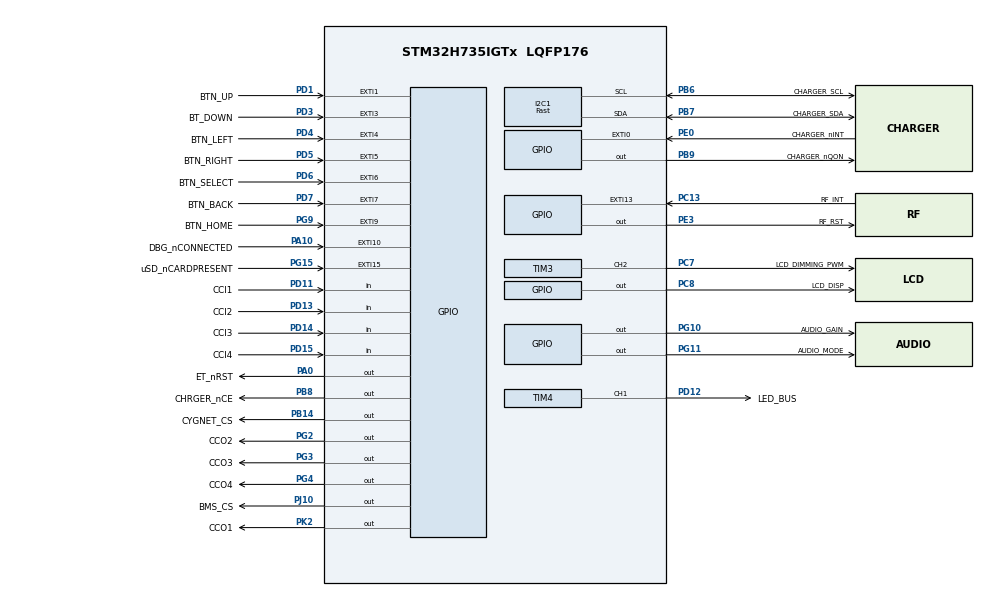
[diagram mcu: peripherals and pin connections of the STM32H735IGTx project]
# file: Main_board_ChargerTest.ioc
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CORTEX_M7.AccessPermission-Cortex_Memory_Protection_Unit_Region1_Settings=MPU_REGION_FULL_ACCESS
CORTEX_M7.BaseAddress-Cortex_Memory_Protection_Unit_Region1_Settings=0x30000000
CORTEX_M7.BaseAddress-Cortex_Memory_Protection_Unit_Region2_Settings=0x30000000
CORTEX_M7.CPU_DCache=Enabled
CORTEX_M7.CPU_ICache=Enabled
CORTEX_M7.DisableExec-Cortex_Memory_Protection_Unit_Region0_Settings=MPU_INSTRUCTION_ACCESS_DISABLE
CORTEX_M7.DisableExec-Cortex_Memory_Protection_Unit_Region1_Settings=MPU_INSTRUCTION_ACCESS_DISABLE
CORTEX_M7.DisableExec-Cortex_Memory_Protection_Unit_Region2_Settings=MPU_INSTRUCTION_ACCESS_DISABLE
CORTEX_M7.Enable-Cortex_Memory_Protection_Unit_Region0_Settings=MPU_REGION_ENABLE
CORTEX_M7.Enable-Cortex_Memory_Protection_Unit_Region1_Settings=MPU_REGION_ENABLE
CORTEX_M7.Enable-Cortex_Memory_Protection_Unit_Region2_Settings=MPU_REGION_ENABLE
CORTEX_M7.IsCacheable-Cortex_Memory_Protection_Unit_Region2_Settings=MPU_ACCESS_CACHEABLE
CORTEX_M7.IsShareable-Cortex_Memory_Protection_Unit_Region0_Settings=MPU_ACCESS_SHAREABLE
CORTEX_M7.MPU_Control=MPU_HFNMI_PRIVDEF
CORTEX_M7.Size-Cortex_Memory_Protection_Unit_Region0_Settings=MPU_REGION_SIZE_4GB
CORTEX_M7.Size-Cortex_Memory_Protection_Unit_Region1_Settings=MPU_REGION_SIZE_32KB
CORTEX_M7.Size-Cortex_Memory_Protection_Unit_Region2_Settings=MPU_REGION_SIZE_512B
CORTEX_M7.SubRegionDisable-Cortex_Memory_Protection_Unit_Region0_Settings=0x87
I2C1.I2C_Speed_Mode=I2C_Fast
I2C1.Speed=50
I2C1.Timing=0xC0102FA1
Mcu.Family=STM32H7
Mcu.Name=STM32H735IGTx
Mcu.Package=LQFP176
NVIC.PriorityGroup=NVIC_PRIORITYGROUP_4
PA0.GPIO_Label=ET_nRST
PA0.Signal=GPIO_Output
PA10.GPIO_Label=DBG_nCONNECTED
PA10.GPIO_ModeDefaultEXTI=GPIO_MODE_IT_FALLING
PA10.Signal=GPXTI10
PA13(JTMS/SWDIO).Mode=Trace_Asynchronous_SW
PA13(JTMS/SWDIO).Signal=DEBUG_JTMS-SWDIO
PA14(JTCK/SWCLK).Mode=Trace_Asynchronous_SW
PA14(JTCK/SWCLK).Signal=DEBUG_JTCK-SWCLK
PB14.GPIO_Label=CYGNET_CS
PB14.Signal=GPIO_Output
PB3(JTDO/TRACESWO).Mode=Trace_Asynchronous_SW
PB3(JTDO/TRACESWO).Signal=DEBUG_JTDO-SWO
PB6.GPIO_Label=CHARGER_SCL
PB6.GPIO_Speed=GPIO_SPEED_FREQ_HIGH
PB6.Mode=I2C
PB6.Signal=I2C1_SCL
PB7.GPIO_Label=CHARGER_SDA
PB7.GPIO_Speed=GPIO_SPEED_FREQ_HIGH
PB7.Mode=I2C
PB7.Signal=I2C1_SDA
PB8.GPIO_Label=CHRGER_nCE
PB8.PinState=GPIO_PIN_SET
PB8.Signal=GPIO_Output
PB9.GPIO_Label=CHARGER_nQON
PB9.PinState=GPIO_PIN_SET
PB9.Signal=GPIO_Output
PC10.GPIO_Label=LCD_R2
PC10.GPIO_Speed=GPIO_SPEED_FREQ_VERY_HIGH
PC10.Signal=LTDC_R2
PC11.GPIO_Label=FLASH_nCS
PC11.Signal=OCTOSPIM_P1_NCS
PC13.GPIO_Label=RF_INT
PC13.Signal=GPXTI13
PC14-OSC32_IN.Mode=LSE-External-Oscillator
PC14-OSC32_IN.Signal=RCC_OSC32_IN
PC15-OSC32_OUT.Mode=LSE-External-Oscillator
PC15-OSC32_OUT.Signal=RCC_OSC32_OUT
PC7.GPIO_Label=LCD_DIMMING_PWM
PC7.Signal=S_TIM3_CH2
PC8.GPIO_Label=LCD_DISP
PC8.Signal=GPIO_Output
PD1.GPIO_Label=BTN_UP
PD1.Signal=GPXTI1
PD11.GPIO_Label=CCI1
PD11.Signal=GPIO_Input
PD12.GPIO_Label=LED_BUS
PD12.GPIO_Speed=GPIO_SPEED_FREQ_MEDIUM
PD12.Signal=S_TIM4_CH1
PD13.GPIO_Label=CCI2
PD13.Signal=GPIO_Input
PD14.GPIO_Label=CCI3
PD14.Signal=GPIO_Input
PD15.GPIO_Label=CCI4
PD15.Signal=GPIO_Input
PD3.GPIO_Label=BT_DOWN
PD3.Signal=GPXTI3
PD4.GPIO_Label=BTN_LEFT
PD4.Signal=GPXTI4
PD5.GPIO_Label=BTN_RIGHT
PD5.Signal=GPXTI5
PD6.GPIO_Label=BTN_SELECT
PD6.Signal=GPXTI6
PD7.GPIO_Label=BTN_BACK
PD7.Signal=GPXTI7
PE0.GPIO_Label=CHARGER_nINT
PE0.GPIO_ModeDefaultEXTI=GPIO_MODE_IT_FALLING
PE0.Signal=GPXTI0
PE3.GPIO_Label=RF_RST
PE3.Signal=GPIO_Output
PF7.GPIO_Label=FLASH_D2
PF7.Signal=OCTOSPIM_P1_IO2
PG10.GPIO_Label=AUDIO_GAIN
PG10.Signal=GPIO_Output
PG11.GPIO_Label=AUDIO_MODE
PG11.Signal=GPIO_Output
PG13.GPIO_Label=BCLK
PG13.Signal=I2S6_CK
PG15.GPIO_Label=uSD_nCARDPRESENT
PG15.GPIO_ModeDefaultEXTI=GPIO_MODE_IT_FALLING
PG15.Signal=GPXTI15
PG2.GPIO_Label=CCO2
PG2.Signal=GPIO_Output
PG3.GPIO_Label=CCO3
PG3.GPIO_Speed=GPIO_SPEED_FREQ_LOW
PG3.Signal=GPIO_Output
PG4.GPIO_Label=CCO4
PG4.Signal=GPIO_Output
PG8.GPIO_Label=LRCK
PG8.Signal=I2S6_WS
PG9.GPIO_Label=BTN_HOME
PG9.Signal=GPXTI9
PH0-OSC_IN.Mode=HSE-External-Oscillator
PH0-OSC_IN.Signal=RCC_OSC_IN
PH1-OSC_OUT.Mode=HSE-External-Oscillator
PH1-OSC_OUT.Signal=RCC_OSC_OUT
PJ10.GPIO_Label=BMS_CS
PJ10.Signal=GPIO_Output
PK2.GPIO_Label=CCO1
PK2.Signal=GPIO_Output
ProjectManager.HeapSize=0x200
ProjectManager.StackSize=0x400
ProjectManager.TargetToolchain=MDK-ARM V5
RCC.ADCFreq_Value=96000671.38671875
RCC.APB1Freq_Value=137500000
RCC.APB2Freq_Value=137500000
RCC.APB3Freq_Value=137500000
RCC.APB4Freq_Value=137500000
RCC.CortexFreq_Value=550000000
RCC.D1PPRE=RCC_APB3_DIV2
RCC.D2PPRE1=RCC_APB1_DIV2
RCC.D2PPRE2=RCC_APB2_DIV2
RCC.D3PPRE=RCC_APB4_DIV2
RCC.DIVM1=2
RCC.DIVM2=2
RCC.DIVN1=44
RCC.DIVN2=15
RCC.DIVP1=1
RCC.DIVQ1=5
RCC.HCLKFreq_Value=275000000
RCC.HPRE=RCC_HCLK_DIV2
RCC.PLL1_VCO_SEL-AdvancedSettings=RCC_PLL1VCOWIDE
RCC.PLL2FRACN=2950
RCC.PLL2_VCI_Range-AdvancedSettings=RCC_PLL2VCIRANGE_3
RCC.PLL3FRACN=0
RCC.PLLFRACN=0
RCC.PLLSourceVirtual=RCC_PLLSOURCE_HSE
RCC.SPI123CLockSelection=RCC_SPI123CLKSOURCE_CLKP
RCC.SYSCLKFreq_VALUE=550000000
RCC.SYSCLKSource=RCC_SYSCLKSOURCE_PLLCLK
RCC.USBCLockSelection=RCC_USBCLKSOURCE_HSI48
RCC.USBFreq_Value=48000000
SH.S_TIM3_CH2.0=TIM3_CH2,Output Compare2 CH2
SH.S_TIM4_CH1.0=TIM4_CH1,PWM Generation1 CH1
TIM3.Channel-Output\ Compare2\ CH2=TIM_CHANNEL_2
TIM4.Channel-PWM\ Generation1\ CH1=TIM_CHANNEL_1
VP_TIM3_VS_ClockSourceINT.Mode=Internal
VP_TIM4_VS_ClockSourceINT.Mode=Internal
board=custom

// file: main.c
/* USER CODE BEGIN Header */
/**
  ******************************************************************************
  * @file           : main.c
  * @brief          : Main program body
  ******************************************************************************
  * @attention
  *
  * Copyright (c) 2024 STMicroelectronics.
  * All rights reserved.
  *
  * This software is licensed under terms that can be found in the LICENSE file
  * in the root directory of this software component.
  * If no LICENSE file comes with this software, it is provided AS-IS.
  *
  ******************************************************************************
  */
/* USER CODE END Header */
#include "main.h"

/* USER CODE BEGIN Includes */

#include "I2C_charger.h"
/* USER CODE END Includes */

I2C_HandleTypeDef hi2c1;

TIM_HandleTypeDef htim3;
TIM_HandleTypeDef htim4;

void SystemClock_Config(void);
static void MPU_Config(void);
static void MX_GPIO_Init(void);
static void MX_I2C1_Init(void);
static void MX_TIM3_Init(void);
static void MX_TIM4_Init(void);

int main(void)
{

  /* MPU Configuration--------------------------------------------------------*/
  MPU_Config();
/* Enable the CPU Cache */

  /* Enable I-Cache---------------------------------------------------------*/
  SCB_EnableICache();

  /* Enable D-Cache---------------------------------------------------------*/
  SCB_EnableDCache();

  /* MCU Configuration--------------------------------------------------------*/

  /* Reset of all peripherals, Initializes the Flash interface and the Systick. */
  HAL_Init();

  /* Configure the system clock */
  SystemClock_Config();

  /* Initialize all configured peripherals */
  MX_GPIO_Init();
  MX_I2C1_Init();
  MX_TIM3_Init();
  MX_TIM4_Init();

  /* Infinite loop */
  /* USER CODE BEGIN WHILE */

	HAL_Delay(500);

  while (1)
  {
    /* USER CODE END WHILE */

    /* USER CODE BEGIN 3 */

	Power_Supply_Thread();

  }
  /* USER CODE END 3 */
}

void SystemClock_Config(void)
{
  RCC_OscInitTypeDef RCC_OscInitStruct = {0};
  RCC_ClkInitTypeDef RCC_ClkInitStruct = {0};

  /** Supply configuration update enable
  */
  HAL_PWREx_ConfigSupply(PWR_DIRECT_SMPS_SUPPLY);

  /** Configure the main internal regulator output voltage
  */
  __HAL_PWR_VOLTAGESCALING_CONFIG(PWR_REGULATOR_VOLTAGE_SCALE0);

  while(!__HAL_PWR_GET_FLAG(PWR_FLAG_VOSRDY)) {}

  /** Initializes the RCC Oscillators according to the specified parameters
  * in the RCC_OscInitTypeDef structure.
  */
  RCC_OscInitStruct.OscillatorType = RCC_OSCILLATORTYPE_HSE;
  RCC_OscInitStruct.HSEState = RCC_HSE_ON;
  RCC_OscInitStruct.PLL.PLLState = RCC_PLL_ON;
  RCC_OscInitStruct.PLL.PLLSource = RCC_PLLSOURCE_HSE;
  RCC_OscInitStruct.PLL.PLLM = 2;
  RCC_OscInitStruct.PLL.PLLN = 44;
  RCC_OscInitStruct.PLL.PLLP = 1;
  RCC_OscInitStruct.PLL.PLLQ = 5;
  RCC_OscInitStruct.PLL.PLLR = 2;
  RCC_OscInitStruct.PLL.PLLRGE = RCC_PLL1VCIRANGE_3;
  RCC_OscInitStruct.PLL.PLLVCOSEL = RCC_PLL1VCOWIDE;
  RCC_OscInitStruct.PLL.PLLFRACN = 0;
  if (HAL_RCC_OscConfig(&RCC_OscInitStruct) != HAL_OK)
  {
    Error_Handler();
  }

  /** Initializes the CPU, AHB and APB buses clocks
  */
  RCC_ClkInitStruct.ClockType = RCC_CLOCKTYPE_HCLK|RCC_CLOCKTYPE_SYSCLK
                              |RCC_CLOCKTYPE_PCLK1|RCC_CLOCKTYPE_PCLK2
                              |RCC_CLOCKTYPE_D3PCLK1|RCC_CLOCKTYPE_D1PCLK1;
  RCC_ClkInitStruct.SYSCLKSource = RCC_SYSCLKSOURCE_PLLCLK;
  RCC_ClkInitStruct.SYSCLKDivider = RCC_SYSCLK_DIV1;
  RCC_ClkInitStruct.AHBCLKDivider = RCC_HCLK_DIV2;
  RCC_ClkInitStruct.APB3CLKDivider = RCC_APB3_DIV2;
  RCC_ClkInitStruct.APB1CLKDivider = RCC_APB1_DIV2;
  RCC_ClkInitStruct.APB2CLKDivider = RCC_APB2_DIV2;
  RCC_ClkInitStruct.APB4CLKDivider = RCC_APB4_DIV2;

  if (HAL_RCC_ClockConfig(&RCC_ClkInitStruct, FLASH_LATENCY_3) != HAL_OK)
  {
    Error_Handler();
  }
}

static void MX_I2C1_Init(void)
{

  hi2c1.Instance = I2C1;
  hi2c1.Init.Timing = 0xC0102FA1;
  hi2c1.Init.OwnAddress1 = 0;
  hi2c1.Init.AddressingMode = I2C_ADDRESSINGMODE_7BIT;
  hi2c1.Init.DualAddressMode = I2C_DUALADDRESS_DISABLE;
  hi2c1.Init.OwnAddress2 = 0;
  hi2c1.Init.OwnAddress2Masks = I2C_OA2_NOMASK;
  hi2c1.Init.GeneralCallMode = I2C_GENERALCALL_DISABLE;
  hi2c1.Init.NoStretchMode = I2C_NOSTRETCH_DISABLE;
  if (HAL_I2C_Init(&hi2c1) != HAL_OK)
  {
    Error_Handler();
  }

  /** Configure Analogue filter
  */
  if (HAL_I2CEx_ConfigAnalogFilter(&hi2c1, I2C_ANALOGFILTER_ENABLE) != HAL_OK)
  {
    Error_Handler();
  }

  /** Configure Digital filter
  */
  if (HAL_I2CEx_ConfigDigitalFilter(&hi2c1, 0) != HAL_OK)
  {
    Error_Handler();
  }

}

static void MX_TIM3_Init(void)
{

  TIM_ClockConfigTypeDef sClockSourceConfig = {0};
  TIM_MasterConfigTypeDef sMasterConfig = {0};
  TIM_OC_InitTypeDef sConfigOC = {0};

  htim3.Instance = TIM3;
  htim3.Init.Prescaler = 0;
  htim3.Init.CounterMode = TIM_COUNTERMODE_UP;
  htim3.Init.Period = 65535;
  htim3.Init.ClockDivision = TIM_CLOCKDIVISION_DIV1;
  htim3.Init.AutoReloadPreload = TIM_AUTORELOAD_PRELOAD_DISABLE;
  if (HAL_TIM_Base_Init(&htim3) != HAL_OK)
  {
    Error_Handler();
  }
  sClockSourceConfig.ClockSource = TIM_CLOCKSOURCE_INTERNAL;
  if (HAL_TIM_ConfigClockSource(&htim3, &sClockSourceConfig) != HAL_OK)
  {
    Error_Handler();
  }
  if (HAL_TIM_OC_Init(&htim3) != HAL_OK)
  {
    Error_Handler();
  }
  sMasterConfig.MasterOutputTrigger = TIM_TRGO_RESET;
  sMasterConfig.MasterSlaveMode = TIM_MASTERSLAVEMODE_DISABLE;
  if (HAL_TIMEx_MasterConfigSynchronization(&htim3, &sMasterConfig) != HAL_OK)
  {
    Error_Handler();
  }
  sConfigOC.OCMode = TIM_OCMODE_TIMING;
  sConfigOC.Pulse = 0;
  sConfigOC.OCPolarity = TIM_OCPOLARITY_HIGH;
  sConfigOC.OCFastMode = TIM_OCFAST_DISABLE;
  if (HAL_TIM_OC_ConfigChannel(&htim3, &sConfigOC, TIM_CHANNEL_2) != HAL_OK)
  {
    Error_Handler();
  }
  HAL_TIM_MspPostInit(&htim3);

}

static void MX_TIM4_Init(void)
{

  TIM_ClockConfigTypeDef sClockSourceConfig = {0};
  TIM_MasterConfigTypeDef sMasterConfig = {0};
  TIM_OC_InitTypeDef sConfigOC = {0};

  htim4.Instance = TIM4;
  htim4.Init.Prescaler = 0;
  htim4.Init.CounterMode = TIM_COUNTERMODE_UP;
  htim4.Init.Period = 65535;
  htim4.Init.ClockDivision = TIM_CLOCKDIVISION_DIV1;
  htim4.Init.AutoReloadPreload = TIM_AUTORELOAD_PRELOAD_DISABLE;
  if (HAL_TIM_Base_Init(&htim4) != HAL_OK)
  {
    Error_Handler();
  }
  sClockSourceConfig.ClockSource = TIM_CLOCKSOURCE_INTERNAL;
  if (HAL_TIM_ConfigClockSource(&htim4, &sClockSourceConfig) != HAL_OK)
  {
    Error_Handler();
  }
  if (HAL_TIM_PWM_Init(&htim4) != HAL_OK)
  {
    Error_Handler();
  }
  sMasterConfig.MasterOutputTrigger = TIM_TRGO_RESET;
  sMasterConfig.MasterSlaveMode = TIM_MASTERSLAVEMODE_DISABLE;
  if (HAL_TIMEx_MasterConfigSynchronization(&htim4, &sMasterConfig) != HAL_OK)
  {
    Error_Handler();
  }
  sConfigOC.OCMode = TIM_OCMODE_PWM1;
  sConfigOC.Pulse = 0;
  sConfigOC.OCPolarity = TIM_OCPOLARITY_HIGH;
  sConfigOC.OCFastMode = TIM_OCFAST_DISABLE;
  if (HAL_TIM_PWM_ConfigChannel(&htim4, &sConfigOC, TIM_CHANNEL_1) != HAL_OK)
  {
    Error_Handler();
  }
  HAL_TIM_MspPostInit(&htim4);

}

static void MX_GPIO_Init(void)
{
  GPIO_InitTypeDef GPIO_InitStruct = {0};

  /* GPIO Ports Clock Enable */
  __HAL_RCC_GPIOE_CLK_ENABLE();
  __HAL_RCC_GPIOC_CLK_ENABLE();
  __HAL_RCC_GPIOF_CLK_ENABLE();
  __HAL_RCC_GPIOH_CLK_ENABLE();
  __HAL_RCC_GPIOA_CLK_ENABLE();
  __HAL_RCC_GPIOB_CLK_ENABLE();
  __HAL_RCC_GPIOD_CLK_ENABLE();
  __HAL_RCC_GPIOJ_CLK_ENABLE();
  __HAL_RCC_GPIOK_CLK_ENABLE();
  __HAL_RCC_GPIOG_CLK_ENABLE();

  /*Configure GPIO pin Output Level */
  HAL_GPIO_WritePin(RF_RST_GPIO_Port, RF_RST_Pin, GPIO_PIN_RESET);

  /*Configure GPIO pin Output Level */
  HAL_GPIO_WritePin(ET_nRST_GPIO_Port, ET_nRST_Pin, GPIO_PIN_RESET);

  /*Configure GPIO pin Output Level */
  HAL_GPIO_WritePin(CYGNET_CS_GPIO_Port, CYGNET_CS_Pin, GPIO_PIN_RESET);

  /*Configure GPIO pin Output Level */
  HAL_GPIO_WritePin(BMS_CS_GPIO_Port, BMS_CS_Pin, GPIO_PIN_RESET);

  /*Configure GPIO pin Output Level */
  HAL_GPIO_WritePin(CCO1_GPIO_Port, CCO1_Pin, GPIO_PIN_RESET);

  /*Configure GPIO pin Output Level */
  HAL_GPIO_WritePin(GPIOG, CCO2_Pin|CCO3_Pin|CCO4_Pin|AUDIO_GAIN_Pin
                          |AUDIO_MODE_Pin, GPIO_PIN_RESET);

  /*Configure GPIO pin Output Level */
  HAL_GPIO_WritePin(LCD_DISP_GPIO_Port, LCD_DISP_Pin, GPIO_PIN_RESET);

  /*Configure GPIO pin Output Level */
  HAL_GPIO_WritePin(GPIOB, CHRGER_nCE_Pin|CHARGER_nQON_Pin, GPIO_PIN_SET);

  /*Configure GPIO pin : RF_RST_Pin */
  GPIO_InitStruct.Pin = RF_RST_Pin;
  GPIO_InitStruct.Mode = GPIO_MODE_OUTPUT_PP;
  GPIO_InitStruct.Pull = GPIO_NOPULL;
  GPIO_InitStruct.Speed = GPIO_SPEED_FREQ_LOW;
  HAL_GPIO_Init(RF_RST_GPIO_Port, &GPIO_InitStruct);

  /*Configure GPIO pin : RF_INT_Pin */
  GPIO_InitStruct.Pin = RF_INT_Pin;
  GPIO_InitStruct.Mode = GPIO_MODE_IT_RISING;
  GPIO_InitStruct.Pull = GPIO_NOPULL;
  HAL_GPIO_Init(RF_INT_GPIO_Port, &GPIO_InitStruct);

  /*Configure GPIO pin : FLASH_D2_Pin */
  GPIO_InitStruct.Pin = FLASH_D2_Pin;
  GPIO_InitStruct.Mode = GPIO_MODE_AF_PP;
  GPIO_InitStruct.Pull = GPIO_NOPULL;
  GPIO_InitStruct.Speed = GPIO_SPEED_FREQ_VERY_HIGH;
  GPIO_InitStruct.Alternate = GPIO_AF10_OCTOSPIM_P1;
  HAL_GPIO_Init(FLASH_D2_GPIO_Port, &GPIO_InitStruct);

  /*Configure GPIO pin : ET_nRST_Pin */
  GPIO_InitStruct.Pin = ET_nRST_Pin;
  GPIO_InitStruct.Mode = GPIO_MODE_OUTPUT_PP;
  GPIO_InitStruct.Pull = GPIO_NOPULL;
  GPIO_InitStruct.Speed = GPIO_SPEED_FREQ_LOW;
  HAL_GPIO_Init(ET_nRST_GPIO_Port, &GPIO_InitStruct);

  /*Configure GPIO pins : CYGNET_CS_Pin CHRGER_nCE_Pin CHARGER_nQON_Pin */
  GPIO_InitStruct.Pin = CYGNET_CS_Pin|CHRGER_nCE_Pin|CHARGER_nQON_Pin;
  GPIO_InitStruct.Mode = GPIO_MODE_OUTPUT_PP;
  GPIO_InitStruct.Pull = GPIO_NOPULL;
  GPIO_InitStruct.Speed = GPIO_SPEED_FREQ_LOW;
  HAL_GPIO_Init(GPIOB, &GPIO_InitStruct);

  /*Configure GPIO pins : CCI1_Pin CCI2_Pin CCI3_Pin CCI4_Pin */
  GPIO_InitStruct.Pin = CCI1_Pin|CCI2_Pin|CCI3_Pin|CCI4_Pin;
  GPIO_InitStruct.Mode = GPIO_MODE_INPUT;
  GPIO_InitStruct.Pull = GPIO_NOPULL;
  HAL_GPIO_Init(GPIOD, &GPIO_InitStruct);

  /*Configure GPIO pin : BMS_CS_Pin */
  GPIO_InitStruct.Pin = BMS_CS_Pin;
  GPIO_InitStruct.Mode = GPIO_MODE_OUTPUT_PP;
  GPIO_InitStruct.Pull = GPIO_NOPULL;
  GPIO_InitStruct.Speed = GPIO_SPEED_FREQ_LOW;
  HAL_GPIO_Init(BMS_CS_GPIO_Port, &GPIO_InitStruct);

  /*Configure GPIO pin : CCO1_Pin */
  GPIO_InitStruct.Pin = CCO1_Pin;
  GPIO_InitStruct.Mode = GPIO_MODE_OUTPUT_PP;
  GPIO_InitStruct.Pull = GPIO_NOPULL;
  GPIO_InitStruct.Speed = GPIO_SPEED_FREQ_LOW;
  HAL_GPIO_Init(CCO1_GPIO_Port, &GPIO_InitStruct);

  /*Configure GPIO pins : CCO2_Pin CCO3_Pin CCO4_Pin AUDIO_GAIN_Pin
                           AUDIO_MODE_Pin */
  GPIO_InitStruct.Pin = CCO2_Pin|CCO3_Pin|CCO4_Pin|AUDIO_GAIN_Pin
                          |AUDIO_MODE_Pin;
  GPIO_InitStruct.Mode = GPIO_MODE_OUTPUT_PP;
  GPIO_InitStruct.Pull = GPIO_NOPULL;
  GPIO_InitStruct.Speed = GPIO_SPEED_FREQ_LOW;
  HAL_GPIO_Init(GPIOG, &GPIO_InitStruct);

  /*Configure GPIO pins : LRCK_Pin BCLK_Pin */
  GPIO_InitStruct.Pin = LRCK_Pin|BCLK_Pin;
  GPIO_InitStruct.Mode = GPIO_MODE_AF_PP;
  GPIO_InitStruct.Pull = GPIO_NOPULL;
  GPIO_InitStruct.Speed = GPIO_SPEED_FREQ_LOW;
  GPIO_InitStruct.Alternate = GPIO_AF5_SPI6;
  HAL_GPIO_Init(GPIOG, &GPIO_InitStruct);

  /*Configure GPIO pin : LCD_DISP_Pin */
  GPIO_InitStruct.Pin = LCD_DISP_Pin;
  GPIO_InitStruct.Mode = GPIO_MODE_OUTPUT_PP;
  GPIO_InitStruct.Pull = GPIO_NOPULL;
  GPIO_InitStruct.Speed = GPIO_SPEED_FREQ_LOW;
  HAL_GPIO_Init(LCD_DISP_GPIO_Port, &GPIO_InitStruct);

  /*Configure GPIO pin : DBG_nCONNECTED_Pin */
  GPIO_InitStruct.Pin = DBG_nCONNECTED_Pin;
  GPIO_InitStruct.Mode = GPIO_MODE_IT_FALLING;
  GPIO_InitStruct.Pull = GPIO_NOPULL;
  HAL_GPIO_Init(DBG_nCONNECTED_GPIO_Port, &GPIO_InitStruct);

  /*Configure GPIO pin : LCD_R2_Pin */
  GPIO_InitStruct.Pin = LCD_R2_Pin;
  GPIO_InitStruct.Mode = GPIO_MODE_AF_PP;
  GPIO_InitStruct.Pull = GPIO_NOPULL;
  GPIO_InitStruct.Speed = GPIO_SPEED_FREQ_VERY_HIGH;
  GPIO_InitStruct.Alternate = GPIO_AF14_LTDC;
  HAL_GPIO_Init(LCD_R2_GPIO_Port, &GPIO_InitStruct);

  /*Configure GPIO pin : FLASH_nCS_Pin */
  GPIO_InitStruct.Pin = FLASH_nCS_Pin;
  GPIO_InitStruct.Mode = GPIO_MODE_AF_PP;
  GPIO_InitStruct.Pull = GPIO_NOPULL;
  GPIO_InitStruct.Speed = GPIO_SPEED_FREQ_VERY_HIGH;
  GPIO_InitStruct.Alternate = GPIO_AF9_OCTOSPIM_P1;
  HAL_GPIO_Init(FLASH_nCS_GPIO_Port, &GPIO_InitStruct);

  /*Configure GPIO pins : BTN_UP_Pin BT_DOWN_Pin BTN_LEFT_Pin BTN_RIGHT_Pin
                           BTN_SELECT_Pin BTN_BACK_Pin */
  GPIO_InitStruct.Pin = BTN_UP_Pin|BT_DOWN_Pin|BTN_LEFT_Pin|BTN_RIGHT_Pin
                          |BTN_SELECT_Pin|BTN_BACK_Pin;
  GPIO_InitStruct.Mode = GPIO_MODE_IT_RISING;
  GPIO_InitStruct.Pull = GPIO_NOPULL;
  HAL_GPIO_Init(GPIOD, &GPIO_InitStruct);

  /*Configure GPIO pin : BTN_HOME_Pin */
  GPIO_InitStruct.Pin = BTN_HOME_Pin;
  GPIO_InitStruct.Mode = GPIO_MODE_IT_RISING;
  GPIO_InitStruct.Pull = GPIO_NOPULL;
  HAL_GPIO_Init(BTN_HOME_GPIO_Port, &GPIO_InitStruct);

  /*Configure GPIO pin : uSD_nCARDPRESENT_Pin */
  GPIO_InitStruct.Pin = uSD_nCARDPRESENT_Pin;
  GPIO_InitStruct.Mode = GPIO_MODE_IT_FALLING;
  GPIO_InitStruct.Pull = GPIO_NOPULL;
  HAL_GPIO_Init(uSD_nCARDPRESENT_GPIO_Port, &GPIO_InitStruct);

  /*Configure GPIO pin : CHARGER_nINT_Pin */
  GPIO_InitStruct.Pin = CHARGER_nINT_Pin;
  GPIO_InitStruct.Mode = GPIO_MODE_IT_FALLING;
  GPIO_InitStruct.Pull = GPIO_NOPULL;
  HAL_GPIO_Init(CHARGER_nINT_GPIO_Port, &GPIO_InitStruct);

}

/* MPU Configuration */

void MPU_Config(void)
{
  MPU_Region_InitTypeDef MPU_InitStruct = {0};

  /* Disables the MPU */
  HAL_MPU_Disable();

  /** Initializes and configures the Region and the memory to be protected
  */
  MPU_InitStruct.Enable = MPU_REGION_ENABLE;
  MPU_InitStruct.Number = MPU_REGION_NUMBER0;
  MPU_InitStruct.BaseAddress = 0x0;
  MPU_InitStruct.Size = MPU_REGION_SIZE_4GB;
  MPU_InitStruct.SubRegionDisable = 0x87;
  MPU_InitStruct.TypeExtField = MPU_TEX_LEVEL0;
  MPU_InitStruct.AccessPermission = MPU_REGION_NO_ACCESS;
  MPU_InitStruct.DisableExec = MPU_INSTRUCTION_ACCESS_DISABLE;
  MPU_InitStruct.IsShareable = MPU_ACCESS_SHAREABLE;
  MPU_InitStruct.IsCacheable = MPU_ACCESS_NOT_CACHEABLE;
  MPU_InitStruct.IsBufferable = MPU_ACCESS_NOT_BUFFERABLE;

  HAL_MPU_ConfigRegion(&MPU_InitStruct);

  /** Initializes and configures the Region and the memory to be protected
  */
  MPU_InitStruct.Number = MPU_REGION_NUMBER1;
  MPU_InitStruct.BaseAddress = 0x30000000;
  MPU_InitStruct.Size = MPU_REGION_SIZE_32KB;
  MPU_InitStruct.SubRegionDisable = 0x0;
  MPU_InitStruct.AccessPermission = MPU_REGION_FULL_ACCESS;
  MPU_InitStruct.IsShareable = MPU_ACCESS_NOT_SHAREABLE;

  HAL_MPU_ConfigRegion(&MPU_InitStruct);

  /** Initializes and configures the Region and the memory to be protected
  */
  MPU_InitStruct.Number = MPU_REGION_NUMBER2;
  MPU_InitStruct.Size = MPU_REGION_SIZE_512B;
  MPU_InitStruct.AccessPermission = MPU_REGION_NO_ACCESS;
  MPU_InitStruct.IsCacheable = MPU_ACCESS_CACHEABLE;

  HAL_MPU_ConfigRegion(&MPU_InitStruct);
  /* Enables the MPU */
  HAL_MPU_Enable(MPU_HFNMI_PRIVDEF);

}

void Error_Handler(void)
{
  __disable_irq();
  while (1)
  {
  }
}
